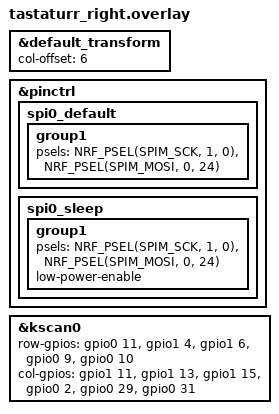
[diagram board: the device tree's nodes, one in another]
#include "tastaturr.dtsi"
&default_transform { // Offset of 3 because the left side has 3 columns
    col-offset = <6>;
};

&pinctrl {
    spi0_default: spi0_default {
        group1 {
            psels = <NRF_PSEL(SPIM_SCK, 1, 0)>,
                    <NRF_PSEL(SPIM_MOSI, 0, 24)>;
        };
    };

    spi0_sleep: spi0_sleep {
        group1 {
            psels = <NRF_PSEL(SPIM_SCK, 1, 0)>,
                    <NRF_PSEL(SPIM_MOSI, 0, 24)>;
            low-power-enable;
        };
    };
};

&kscan0 {
    row-gpios
        = <&gpio0 11 (GPIO_ACTIVE_HIGH | GPIO_PULL_DOWN)>
        , <&gpio1 4 (GPIO_ACTIVE_HIGH | GPIO_PULL_DOWN)>
        , <&gpio1 6 (GPIO_ACTIVE_HIGH | GPIO_PULL_DOWN)>
        , <&gpio0 9 (GPIO_ACTIVE_HIGH | GPIO_PULL_DOWN)>
        , <&gpio0 10 (GPIO_ACTIVE_HIGH | GPIO_PULL_DOWN)>
        ;
    col-gpios
        = <&gpio1 11 GPIO_ACTIVE_HIGH>
        , <&gpio1 13 GPIO_ACTIVE_HIGH>
        , <&gpio1 15 GPIO_ACTIVE_HIGH>
        , <&gpio0 2 GPIO_ACTIVE_HIGH>
        , <&gpio0 29 GPIO_ACTIVE_HIGH>
        , <&gpio0 31 GPIO_ACTIVE_HIGH>
        ;
};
